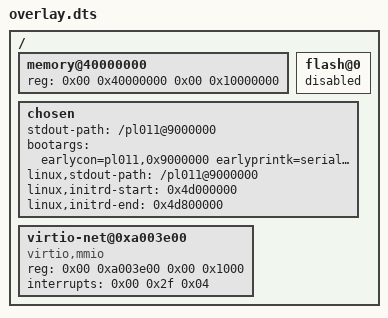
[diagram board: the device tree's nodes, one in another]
/*
 * Copyright 2024, UNSW
 *
 * SPDX-License-Identifier: BSD-2-Clause
 */
/ {
    /* Need to specify how much RAM the guest will have */
    memory@40000000 {
        device_type = "memory";
        reg = <0x00 0x40000000 0x00 0x10000000>;
    };

    flash@0 {
        status = "disabled";
    };

    chosen {
        stdout-path = "/pl011@9000000";
        bootargs = "earlycon=pl011,0x9000000 earlyprintk=serial debug loglevel=8";
        linux,stdout-path = "/pl011@9000000";
        linux,initrd-start = <0x4d000000>;
        linux,initrd-end = <0x4d800000>;
    };

    virtio-net@0xa003e00 {
		compatible = "virtio,mmio";
		reg = <0x00 0xa003e00 0x00 0x1000>;
		interrupts = <0x00 0x2f 0x04>;
	};
};
